# NM1810AE_v1 register map
File version: 1.0
Registers are 32-bit, read-write, reset 0x0 unless marked. A register's access mark holds for its fields unless they carry their own. Offsets are from the block's base; [hi:lo] are bit positions; 'fields as' and 'values as' point back to an identical list.

## BPWM — BPWM Register Map
Base 0x40140000
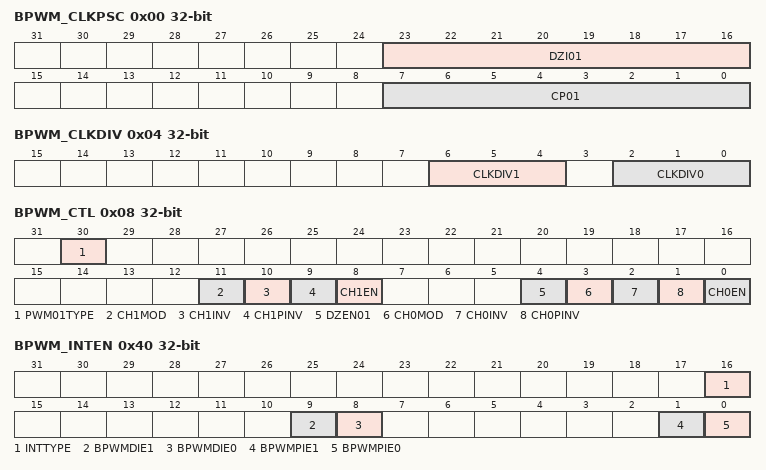
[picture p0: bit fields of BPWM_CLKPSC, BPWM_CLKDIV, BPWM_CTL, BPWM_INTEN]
0x00 BPWM_CLKPSC — Basic PWM Pre-scalar Register
  [23:16] DZI01 — Dead-zone Interval for Pair of Channel 0 and Channel 1. These 8-bit determine the Dead-zone length.
  [7:0] CP01 — Clock Prescaler. Clock input is divided by (CP01 + 1) before it is fed to the corresponding PWM-timer
0x04 BPWM_CLKDIV — Basic PWM Clock Source Divider Select Register
  [6:4] CLKDIV1 — PWM Timer 1 Clock Source Divider Selection. Select clock source divider for PWM timer 1.
    0=1/2; 1=1/4; 2=1/8; 3=1/16; 4=1
  [2:0] CLKDIV0 — PWM Timer 0 Clock Source Divider Selection. Select clock source divider for PWM timer 0. (Table is the same as CLKDIV1)
0x08 BPWM_CTL — Basic PWM Control Register
  [30] PWM01TYPE — PWM01 Aligned Type Selection Bit
    0=Edge-aligned type; 1=Center-aligned type
  [11] CH1MOD — PWM-timer 1 Auto-reload/One-shot Mode. Note: If there is a transition at this bit, it will cause PERIOD1 and CMP1 be cleared.
    0=One-shot mode; 1=Auto-reload mode
  [10] CH1INV — PWM-timer 1 Output Inverter Enable
    0=Inverter Disabled; 1=Inverter Enabled
  [9] CH1PINV — PWM-timer 1 Output Polar Inverse Enable Bit
    0=PWM1 output polar inverse Disabled; 1=PWM1 output polar inverse Enabled
  [8] CH1EN — PWM-timer 1 Enable Bit
    0=Corresponding PWM-Timer Stopped; 1=Corresponding PWM-Timer Start Running
  [4] DZEN01 — Dead-zone 0 Generator Enable Bit. Note: When Dead-zone generator is enabled, the pair of PWM0 and PWM1 becomes a complementary pair.
    0=Dead-zone 0 Generato Disabled; 1=Dead-zone 0 Generato Enabled
  [3] CH0MOD — PWM-timer 0 Auto-reload/One-shot Mode. Note: If there is a transition at this bit, it will cause PWM_PERIOD0 and CMP0 be cleared.
    0=One-shot mode; 1=Auto-reload mode
  [2] CH0INV — PWM-timer 0 Output Inverter Enable Bit
    0=Inverter Disabled; 1=Inverter Enabled
  [1] CH0PINV — PWM-timer 0 Output Polar Inverse Enable Bit
    0=PWM0 output polar inverse Disabled; 1=PWM0 output polar inverse Enabled
  [0] CH0EN — PWM-timer 0 Enable Bit
    0=The corresponding PWM-Timer stops running; 1=The corresponding PWM-Timer starts running
0x0C BPWM_PERIOD0 — Basic PWM Period Counter Register 0
  [15:0] PERIOD — Basic PWM Period Counter Register. PERIOD data determines the PWM period. Note: Any write to PERIOD will take effect in next PWM cycle. Note: When PWM operating at Center-aligned type, PERIOD value should be set between 0x0000 to 0xFFFE. If PERIOD equal to 0xFFFF, the PWM will work unpredictable. Note: When PERIOD value is set to 0, PWM output is always high.
0x10 BPWM_CMPDAT0 — Basic PWM Comparator Register 0
  [15:0] CMP — PWM Comparator Register. CMP determines the PWM duty. Note: Any write to PERIOD will take effect in next PWM cycle.
0x14 BPWM_DAT0 ro — Basic PWM Data Register 0
  [15:0] PDR — PWM Data Register. User can monitor PDR to know the current value in 16-bit counter.
0x18 BPWM_PERIOD1 — Basic PWM Period Counter Register 0
  fields as BPWM_PERIOD0
0x1C BPWM_CMPDAT1 — Basic PWM Comparator Register 0
  fields as BPWM_CMPDAT0
0x20 BPWM_DAT1 ro — Basic PWM Data Register 0
  fields as BPWM_DAT0
0x40 BPWM_INTEN — Basic PWM Interrupt Enable Register
  [16] INTTYPE — BPWM Interrupt Period Type Selection Bit. Note: This bit is effective when BPWM in Center-aligned type only.
    0=BPWMIFn will be set if BPWM counter underflow; 1=BPWMIFn will be set if BPWM counter matches PERIODn register
  [9] BPWMDIE1 — BPWM Channel 1 Duty Interrupt Enable Bit
    0=BPWM Channel 1 Duty Interrupt Disabled; 1=BPWM Channel 1 Duty Interrupt Enabled
  [8] BPWMDIE0 — BPWM Channel 0 Duty Interrupt Enable Bit
    0=BPWM Channel 0 Duty Interrupt Disabled; 1=BPWM Channel 0 Duty Interrupt Enabled
  [1] BPWMPIE1 — BPWM Channel 1 Period Interrupt Enable Bit
    0=BPWM Channel 1 Period Interrupt Disabled; 1=BPWM Channel 1 Period Interrupt Enabled
  [0] BPWMPIE0 — BPWM Channel 0 Period Interrupt Enable Bit
    0=BPWM Channel 0 Period Interrupt Disabled; 1=BPWM Channel 0 Period Interrupt Enabled
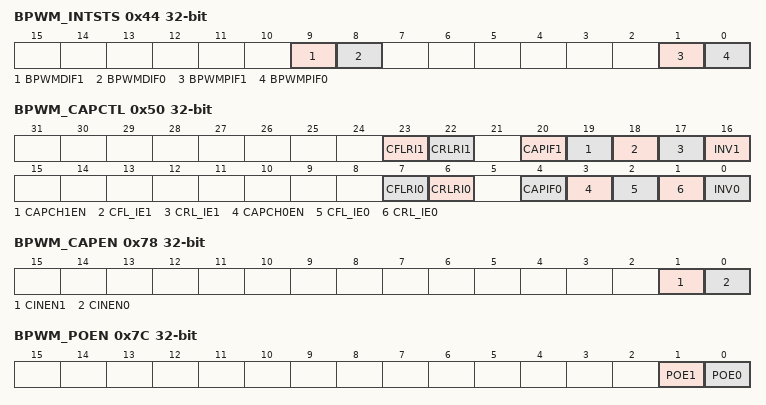
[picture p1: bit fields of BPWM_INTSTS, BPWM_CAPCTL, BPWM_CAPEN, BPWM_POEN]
0x44 BPWM_INTSTS — Basic PWM Interrupt Indication Register
  [9] BPWMDIF1 — BPWM Channel 1 Duty Interrupt Flag. Flag is set by hardware when channel 1 BPWM counter down count and reaches CMP1, software can clear this bit by writing a one to it. Note: If CMP equal to PERIOD, this flag is not working in Edge-aligned type selection
  [8] BPWMDIF0 — BPWM Channel 0 Duty Interrupt Flag. Flag is set by hardware when channel 0 BPWM counter down count and reaches CMP0, software can clear this bit by writing a one to it. Note: If CMP equal to PERIOD, this flag is not working in Edge-aligned type selection
  [1] BPWMPIF1 — BPWM Channel 1 Period Interrupt Status. This bit is set by hardware when BPWM1 counter reaches the requirement of interrupt (depend on INTTYPE bit of PWM_INTEN register), software can write 1 to clear this bit to 0.
  [0] BPWMPIF0 — BPWM Channel 0 Period Interrupt Status. This bit is set by hardware when BPWM0 counter reaches the requirement of interrupt (depend on INTTYPE bit of PWM_INTEN register), software can write 1 to clear this bit to 0.
0x50 BPWM_CAPCTL — Basic PWM Capture Control Register
  [23] CFLRI1 — CFLR1 Latched Indicator Bit. When BPWM input channel 1 has a falling transition, CFLR1 was latched with the value of BPWM down-counter and this bit is set by hardware. Software can write 1 to clear this bit to 0
  [22] CRLRI1 — CRLR1 Latched Indicator Bit. When BPWM input channel 1 has a rising transition, CRLR1 was latched with the value of BPWM down-counter and this bit is set by hardware. Software can write 1 to clear this bit to0.
  [20] CAPIF1 — Channel 1 Capture Interrupt Indication Flag. Write 1 to clear this bit to 0.
  [19] CAPCH1EN — Channel 1 Capture Function Enable Bit. When Enabled, Capture latched the BPWM-counter and saved to CRLR (Rising latch) and CFLR (Falling latch). When Disabled, Capture does not update CRLR and CFLR, and disable PWM channel 1 Interrupt.
    0=Capture function on BPWM channel 1 Disabled; 1=Capture function on BPWM channel 1 Enabled
  [18] CFL_IE1 — Channel 1 Falling Latch Interrupt Enable. When Enabled, if Capture detects BPWM channel 1 has falling transition, Capture will issue an Interrupt.
    0=Falling latch interrupt Disabled; 1=Falling latch interrupt Enabled
  [17] CRL_IE1 — Channel 1 Rising Latch Interrupt Enable Bit. When Enabled, if Capture detects BPWM channel 1 has rising transition, Capture will issue an Interrupt.
    0=Rising latch interrupt Disabled; 1=Rising latch interrupt Enabled
  [16] INV1 — Channel 1 Inverter Enable Bit
    0=Inverter Disabled; 1=Inverter Enabled. Reverse the input signal from GPIO before fed to Capture timer
  [7] CFLRI0 — BPWM_CAPDRL0 Latched Indicator Bit. When BPWM input channel 0 has a falling transition, BPWM_CAPDRL0 was latched with the value of BPWM down-counter and this bit is set by hardware. Software can write 1 to clear this bit to0.
  [6] CRLRI0 — BPWM_CAPDRL0Latched Indicator Bit. When BPWM input channel 0 has a rising transition, BPWM_CAPDRL0 was latched with the value of BPWM down-counter and this bit is set by hardware. Software can write 1 to clear this bit to 0.
  [4] CAPIF0 — Channel 0 Capture Interrupt Indication Flag. Write 1 to clear this bit to 0.
  [3] CAPCH0EN — Channel 0 Capture Function Enable Bit. When Enabled, Capture latched the BPWM-counter value and saved to CRLR (Rising latch) and CFLR (Falling latch). When Disabled, Capture does not update CRLR and CFLR, and disable BPWM channel 0 Interrupt.
    0=Capture function on BPWM channel 0 Disabled; 1=Capture function on BPWM channel 0 Enabled
  [2] CFL_IE0 — Channel 0 Falling Latch Interrupt Enable BIt. When Enabled, if Capture detects BPWM channel 0 has falling transition, Capture will issue an Interrupt.
    values as CFL_IE1
  [1] CRL_IE0 — Channel 0 Rising Latch Interrupt Enable Bit. When Enabled, if Capture detects BPWM channel 0 has rising transition, Capture will issue an Interrupt.
    values as CRL_IE1
  [0] INV0 — Channel 0 Inverter Enable Bit
    values as INV1
0x58 BPWM_CAPDRL0 ro — Basic PWM Capture Rising Latch Register (Channel 0)
  [15:0] CRLR — Capture Rising Latch Register. Latch the BPWM counter when Channel 0/1 has rising transition.
0x5C BPWM_CAPDFL0 ro — Basic PWM Capture Falling Latch Register (Channel 0)
  [15:0] CFLR — Capture Falling Latch Register. Latch the BPWM counter when Channel 0/1 has Falling transition.
0x60 BPWM_CAPDRL1 ro — Basic PWM Capture Rising Latch Register (Channel 0)
  fields as BPWM_CAPDRL0
0x64 BPWM_CAPDFL1 ro — Basic PWM Capture Falling Latch Register (Channel 0)
  fields as BPWM_CAPDFL0
0x78 BPWM_CAPEN — Basic PWM Capture Input Enable Register
  [1] CINEN1 — Channel 1 Capture Input Enable Bit
    0=BPWM Channel 1 capture input path Disabled. The input of BPWM channel 1 capture function is always regarded as 0; 1=BPWM Channel 1 capture input path Enabled. The input of BPWM channel 1 capture function comes from correlative multifunction pin if GPIO multi-function is set as PWM21
  [0] CINEN0 — Channel 0 Capture Input Enable Bit
    0=BPWM Channel 0 capture input path Disabled. The input of BPWM channel 0 capture function is always regarded as 0; 1=BPWM Channel 0 capture input path Enabled. The input of BPWM channel 0 capture function comes from correlative multifunction pin if GPIO multi-function is set as PWM20
0x7C BPWM_POEN — Basic PWM Output Enable
  [1] POE1 — Channel 1 Output Enable Register. Note: The corresponding GPIO pin must also be switched to BPWM function
    0=BPWM channel 1 output to pin Disabled; 1=BPWM channel 1 output to pin Enabled
  [0] POE0 — Channel 0 Output Enable Register. Note: The corresponding GPIO pin must also be switched to BPWM function
    0=BPWM channel 0 output to pin Disabled; 1=BPWM channel 0 output to pin Enabled
